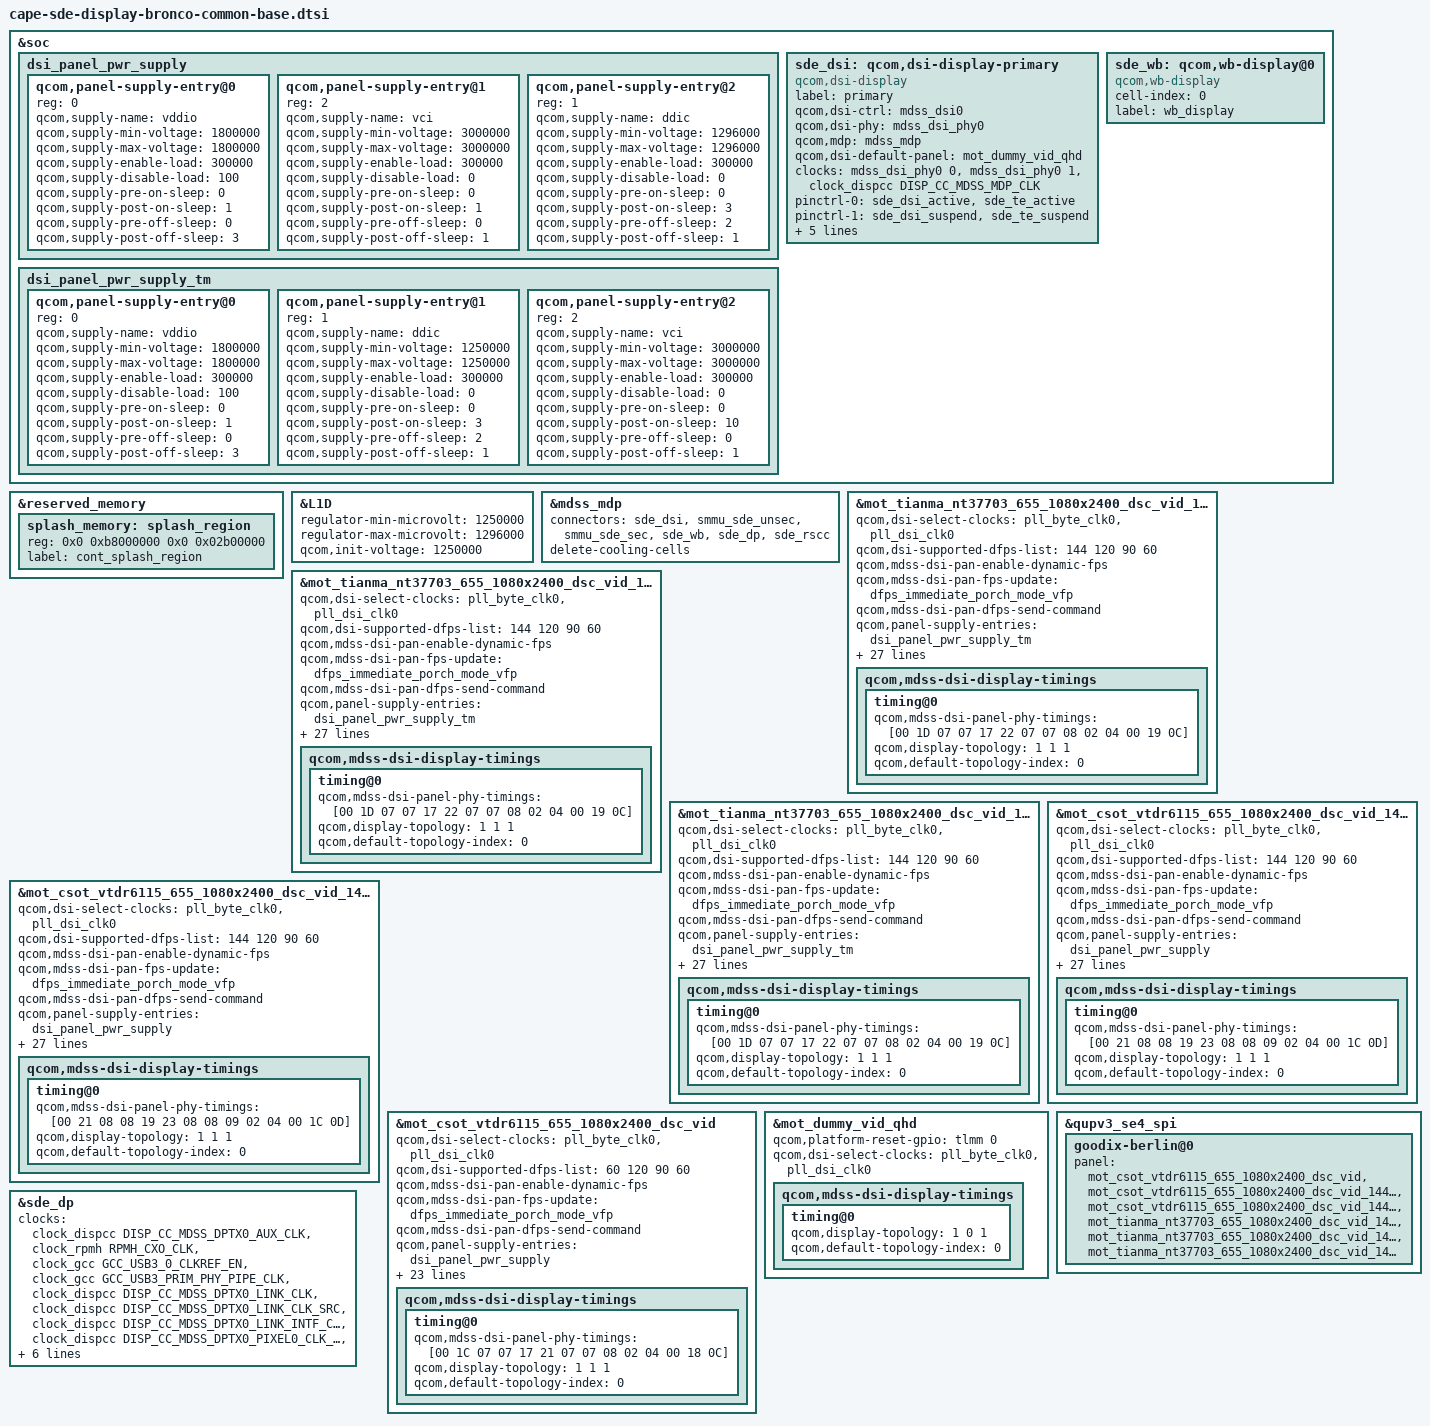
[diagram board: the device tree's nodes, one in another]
/*
   this is original from cape-sde-display-hiphi-common-base.dtsi
*/
#include <dt-bindings/clock/qcom,gcc-waipio.h>
#include <dt-bindings/clock/qcom,rpmh.h>
#include "cape-sde-display-pinctrl.dtsi"
#include "dsi-panel-mot-dummy-qhd-video.dtsi"
#include <dt-bindings/clock/qcom,dispcc-waipio.h>
#include "dsi-panel-mot-csot-vtdr6115-655-1080x2400-dsc-video-common.dtsi"
#include "dsi-panel-mot-csot-vtdr6115-655-1080x2400-dsc-video-144hz-common.dtsi"
#include "dsi-panel-mot-csot-vtdr6115-655-1080x2400-dsc-video-144hz-common-v1.dtsi"
#include "dsi-panel-mot-tianma-nt37703-655-1080x2400-dsc-video-144hz-common.dtsi"
#include "dsi-panel-mot-tianma-nt37703-655-1080x2400-dsc-video-144hz-common-v1.dtsi"
#include "dsi-panel-mot-tianma-nt37703-655-1080x2400-dsc-video-144hz-common-v2.dtsi"

&soc {

	dsi_panel_pwr_supply: dsi_panel_pwr_supply {
		#address-cells = <1>;
		#size-cells = <0>;

		qcom,panel-supply-entry@0 {
			reg = <0>;
			qcom,supply-name = "vddio";
			qcom,supply-min-voltage = <1800000>;
			qcom,supply-max-voltage = <1800000>;
			qcom,supply-enable-load = <300000>;
			qcom,supply-disable-load = <100>;
			qcom,supply-pre-on-sleep = <0>;
			qcom,supply-post-on-sleep = <1>;
			qcom,supply-pre-off-sleep = <0>;
			qcom,supply-post-off-sleep = <3>;
		};

		qcom,panel-supply-entry@1 {
			reg = <2>;
			qcom,supply-name = "vci";
			qcom,supply-min-voltage = <3000000>;
			qcom,supply-max-voltage = <3000000>;
			qcom,supply-enable-load = <300000>;
			qcom,supply-disable-load = <0>;
			qcom,supply-pre-on-sleep = <0>;
			qcom,supply-post-on-sleep = <1>;
			qcom,supply-pre-off-sleep = <0>;
			qcom,supply-post-off-sleep = <1>;
		};

		qcom,panel-supply-entry@2 {
			reg = <1>;
			qcom,supply-name = "ddic";
			qcom,supply-min-voltage = <1296000>;
			qcom,supply-max-voltage = <1296000>;
			qcom,supply-enable-load = <300000>;
			qcom,supply-disable-load = <0>;
			qcom,supply-pre-on-sleep = <0>;
			qcom,supply-post-on-sleep = <3>;
			qcom,supply-pre-off-sleep = <2>;
			qcom,supply-post-off-sleep = <1>;
		};
	};

	dsi_panel_pwr_supply_tm: dsi_panel_pwr_supply_tm {
		#address-cells = <1>;
		#size-cells = <0>;

		qcom,panel-supply-entry@0 {
			reg = <0>;
			qcom,supply-name = "vddio";
			qcom,supply-min-voltage = <1800000>;
			qcom,supply-max-voltage = <1800000>;
			qcom,supply-enable-load = <300000>;
			qcom,supply-disable-load = <100>;
			qcom,supply-pre-on-sleep = <0>;
			qcom,supply-post-on-sleep = <1>;
			qcom,supply-pre-off-sleep = <0>;
			qcom,supply-post-off-sleep = <3>;
		};


		qcom,panel-supply-entry@1 {
			reg = <1>;
			qcom,supply-name = "ddic";
			qcom,supply-min-voltage = <1250000>;
			qcom,supply-max-voltage = <1250000>;
			qcom,supply-enable-load = <300000>;
			qcom,supply-disable-load = <0>;
			qcom,supply-pre-on-sleep = <0>;
			qcom,supply-post-on-sleep = <3>;
			qcom,supply-pre-off-sleep = <2>;
			qcom,supply-post-off-sleep = <1>;
		};

		qcom,panel-supply-entry@2 {
			reg = <2>;
			qcom,supply-name = "vci";
			qcom,supply-min-voltage = <3000000>;
			qcom,supply-max-voltage = <3000000>;
			qcom,supply-enable-load = <300000>;
			qcom,supply-disable-load = <0>;
			qcom,supply-pre-on-sleep = <0>;
			qcom,supply-post-on-sleep = <10>;
			qcom,supply-pre-off-sleep = <0>;
			qcom,supply-post-off-sleep = <1>;
		};

	};

	sde_dsi: qcom,dsi-display-primary {
		compatible = "qcom,dsi-display";
		label = "primary";

		qcom,dsi-ctrl = <&mdss_dsi0>;
		qcom,dsi-phy = <&mdss_dsi_phy0>;

		qcom,mdp = <&mdss_mdp>;
		qcom,dsi-default-panel = <&mot_dummy_vid_qhd>;
	};
};


&soc {
	sde_wb: qcom,wb-display@0 {
		compatible = "qcom,wb-display";
		cell-index = <0>;
		label = "wb_display";
	};
};

&reserved_memory {
	splash_memory: splash_region {
		reg = <0x0 0xb8000000 0x0 0x02b00000>;
		label = "cont_splash_region";
	};
};

&sde_dsi {
	clocks = <&mdss_dsi_phy0 0>,
			<&mdss_dsi_phy0 1>,

			 /*
			  * Currently the dsi clock handles are under the dsi
			  * controller DT node. As soon as the controller probe
			  * finishes, the dispcc sync state can get called before
			  * the dsi_display probe potentially disturbing the clock
			  * votes for cont_splash use case. Hence we are no longer
			  * protected by the component model in this case against the
			  * disp cc sync state getting triggered after the dsi_ctrl
			  * probe. To protect against this incorrect sync state trigger
			  * add this dummy MDP clk vote handle to the dsi_display
			  * DT node. Since the dsi_display driver does not parse
			  * MDP clock nodes, no actual vote shall be added and this
			  * change is done just to satisfy sync state requirements.
			  */
			 <&clock_dispcc DISP_CC_MDSS_MDP_CLK>;
	clock-names = "pll_byte_clk0", "pll_dsi_clk0",
			"mdp_core_clk";

	pinctrl-names = "panel_active", "panel_suspend";
	pinctrl-0 = <&sde_dsi_active &sde_te_active>;
	pinctrl-1 = <&sde_dsi_suspend &sde_te_suspend>;

	qcom,platform-te-gpio = <&tlmm 86 0>;
	qcom,panel-te-source = <0>;

	vddio-supply = <&L12C>;
	ddic-supply = <&L1D>;
	vci-supply = <&L13C>;
};

&L1D {
	regulator-min-microvolt = <1250000>;
	regulator-max-microvolt = <1296000>;
	qcom,init-voltage = <1250000>;
};

&mdss_mdp {
	connectors = <&sde_dsi &smmu_sde_unsec &smmu_sde_sec &sde_wb &sde_dp &sde_rscc>;
	delete-cooling-cells;
};

&mot_tianma_nt37703_655_1080x2400_dsc_vid_144hz_v2 {
	qcom,dsi-select-clocks = "pll_byte_clk0", "pll_dsi_clk0";

	qcom,dsi-supported-dfps-list = <144 120 90 60>;
	qcom,mdss-dsi-pan-enable-dynamic-fps;
	qcom,mdss-dsi-pan-fps-update = "dfps_immediate_porch_mode_vfp";
	qcom,mdss-dsi-pan-dfps-send-command;

	//qcom,dsi-dyn-clk-enable;

	qcom,panel-supply-entries = <&dsi_panel_pwr_supply_tm>;
	qcom,mdss-dsi-no-panel-on-read-support;
	qcom,mdss-dsi-bl-pmic-control-type = "bl_ctrl_dcs";
	qcom,mdss-dsi-bl-min-level = <1>;
	qcom,mdss-dsi-bl-max-level = <4095>;
	//qcom,mdss-dsi-bl-default-level = <1024>;
	qcom,mdss-brightness-max-level = <4095>;
	qcom,platform-reset-gpio = <&tlmm 0 0>;
	qcom,bl-dsc-cmd-state = "dsi_hs_mode";
	qcom,mdss-dsi-bl-is-exponent;

	qcom,mdss-dsi-panel-hdr-enabled;
	qcom,mdss-dsi-panel-hdr-color-primaries = <14950 15750 34000
	        16000 13000 35500 7000 2500>;
	qcom,mdss-dsi-panel-peak-brightness = <5000000>;
	qcom,mdss-dsi-panel-blackness-level = <100>;

	qcom,mdss-dsi-panel-status-check-mode = "reg_read";
	qcom,mdss-dsi-panel-status-command = [06 01 00 01 00 00 01 0A];
	qcom,mdss-dsi-panel-status-command-state = "dsi_lp_mode";
	qcom,mdss-dsi-panel-status-value = <0x9C>;
	qcom,mdss-dsi-panel-status-read-length = <1>;
	qcom,esd-check-enabled;

	qcom,cellid-read-enabled;
	qcom,mdss-dsi-panel-cellid-read-length = <23>;
	qcom,mdss-dsi-panel-cellid-command = [
		39 01 00 00 00 00 03 F0 AA 10
		06 01 00 01 00 00 01 AC];

	qcom,mdss-dsi-display-timings {
		timing@0 {
			//qcom,mdss-dsi-panel-clockrate = <400000000>;
			qcom,mdss-dsi-panel-phy-timings = [00 1D 07 07 17 22 07
				07 08 02 04 00 19 0C];
			qcom,display-topology = <1 1 1>;
			qcom,default-topology-index = <0>;
		};
	};
};

&mot_tianma_nt37703_655_1080x2400_dsc_vid_144hz_v1 {
	qcom,dsi-select-clocks = "pll_byte_clk0", "pll_dsi_clk0";

	qcom,dsi-supported-dfps-list = <144 120 90 60>;
	qcom,mdss-dsi-pan-enable-dynamic-fps;
	qcom,mdss-dsi-pan-fps-update = "dfps_immediate_porch_mode_vfp";
	qcom,mdss-dsi-pan-dfps-send-command;

	//qcom,dsi-dyn-clk-enable;

	qcom,panel-supply-entries = <&dsi_panel_pwr_supply_tm>;
	qcom,mdss-dsi-no-panel-on-read-support;
	qcom,mdss-dsi-bl-pmic-control-type = "bl_ctrl_dcs";
	qcom,mdss-dsi-bl-min-level = <1>;
	qcom,mdss-dsi-bl-max-level = <4095>;
	//qcom,mdss-dsi-bl-default-level = <1024>;
	qcom,mdss-brightness-max-level = <4095>;
	qcom,platform-reset-gpio = <&tlmm 0 0>;
	qcom,bl-dsc-cmd-state = "dsi_hs_mode";
	qcom,mdss-dsi-bl-is-exponent;

	qcom,mdss-dsi-panel-hdr-enabled;
	qcom,mdss-dsi-panel-hdr-color-primaries = <14950 15750 34000
	        16000 13000 35500 7000 2500>;
	qcom,mdss-dsi-panel-peak-brightness = <5000000>;
	qcom,mdss-dsi-panel-blackness-level = <100>;

	qcom,mdss-dsi-panel-status-check-mode = "reg_read";
	qcom,mdss-dsi-panel-status-command = [06 01 00 01 00 00 01 0A];
	qcom,mdss-dsi-panel-status-command-state = "dsi_lp_mode";
	qcom,mdss-dsi-panel-status-value = <0x9C>;
	qcom,mdss-dsi-panel-status-read-length = <1>;
	qcom,esd-check-enabled;

	qcom,cellid-read-enabled;
	qcom,mdss-dsi-panel-cellid-read-length = <23>;
	qcom,mdss-dsi-panel-cellid-command = [
		39 01 00 00 00 00 03 F0 AA 10
		06 01 00 01 00 00 01 AC];

	qcom,mdss-dsi-display-timings {
		timing@0 {
			//qcom,mdss-dsi-panel-clockrate = <400000000>;
			qcom,mdss-dsi-panel-phy-timings = [00 1D 07 07 17 22 07
				07 08 02 04 00 19 0C];
			qcom,display-topology = <1 1 1>;
			qcom,default-topology-index = <0>;
		};
	};
};

&mot_tianma_nt37703_655_1080x2400_dsc_vid_144hz {
	qcom,dsi-select-clocks = "pll_byte_clk0", "pll_dsi_clk0";

	qcom,dsi-supported-dfps-list = <144 120 90 60>;
	qcom,mdss-dsi-pan-enable-dynamic-fps;
	qcom,mdss-dsi-pan-fps-update = "dfps_immediate_porch_mode_vfp";
	qcom,mdss-dsi-pan-dfps-send-command;

	//qcom,dsi-dyn-clk-enable;

	qcom,panel-supply-entries = <&dsi_panel_pwr_supply_tm>;
	qcom,mdss-dsi-no-panel-on-read-support;
	qcom,mdss-dsi-bl-pmic-control-type = "bl_ctrl_dcs";
	qcom,mdss-dsi-bl-min-level = <1>;
	qcom,mdss-dsi-bl-max-level = <4095>;
	//qcom,mdss-dsi-bl-default-level = <1024>;
	qcom,mdss-brightness-max-level = <4095>;
	qcom,platform-reset-gpio = <&tlmm 0 0>;
	qcom,bl-dsc-cmd-state = "dsi_hs_mode";
	qcom,mdss-dsi-bl-is-exponent;

	qcom,mdss-dsi-panel-hdr-enabled;
	qcom,mdss-dsi-panel-hdr-color-primaries = <14950 15750 34000
	        16000 13000 35500 7000 2500>;
	qcom,mdss-dsi-panel-peak-brightness = <5000000>;
	qcom,mdss-dsi-panel-blackness-level = <100>;

	qcom,mdss-dsi-panel-status-check-mode = "reg_read";
	qcom,mdss-dsi-panel-status-command = [06 01 00 01 00 00 01 0A];
	qcom,mdss-dsi-panel-status-command-state = "dsi_lp_mode";
	qcom,mdss-dsi-panel-status-value = <0x9C>;
	qcom,mdss-dsi-panel-status-read-length = <1>;
	qcom,esd-check-enabled;

	qcom,cellid-read-enabled;
	qcom,mdss-dsi-panel-cellid-read-length = <23>;
	qcom,mdss-dsi-panel-cellid-command = [
		39 01 00 00 00 00 03 F0 AA 10
		06 01 00 01 00 00 01 AC];

	qcom,mdss-dsi-display-timings {
		timing@0 {
			//qcom,mdss-dsi-panel-clockrate = <400000000>;
			qcom,mdss-dsi-panel-phy-timings = [00 1D 07 07 17 22 07
				07 08 02 04 00 19 0C];
			qcom,display-topology = <1 1 1>;
			qcom,default-topology-index = <0>;
		};
	};
};

&mot_csot_vtdr6115_655_1080x2400_dsc_vid_144hz_v1 {
	qcom,dsi-select-clocks = "pll_byte_clk0", "pll_dsi_clk0";

	qcom,dsi-supported-dfps-list = <144 120 90 60>;
	qcom,mdss-dsi-pan-enable-dynamic-fps;
	qcom,mdss-dsi-pan-fps-update = "dfps_immediate_porch_mode_vfp";
	qcom,mdss-dsi-pan-dfps-send-command;

	//qcom,dsi-dyn-clk-enable;

	qcom,panel-supply-entries = <&dsi_panel_pwr_supply>;
	qcom,mdss-dsi-no-panel-on-read-support;
	qcom,mdss-dsi-bl-pmic-control-type = "bl_ctrl_dcs";
	qcom,mdss-dsi-bl-min-level = <1>;
	qcom,mdss-dsi-bl-max-level = <4095>;
	//qcom,mdss-dsi-bl-default-level = <1024>;
	qcom,mdss-brightness-max-level = <4095>;
	qcom,platform-reset-gpio = <&tlmm 0 0>;
	qcom,bl-dsc-cmd-state = "dsi_hs_mode";
	qcom,mdss-dsi-bl-is-exponent;

	qcom,mdss-dsi-panel-hdr-enabled;
	qcom,mdss-dsi-panel-hdr-color-primaries = <14950 15750 34000
	        16000 13000 35500 7000 2500>;
	qcom,mdss-dsi-panel-peak-brightness = <5000000>;
	qcom,mdss-dsi-panel-blackness-level = <100>;

	qcom,mdss-dsi-panel-status-check-mode = "reg_read";
	qcom,mdss-dsi-panel-status-command = [06 01 00 01 00 00 01 66];
	qcom,mdss-dsi-panel-status-command-state = "dsi_lp_mode";
	qcom,mdss-dsi-panel-status-value = <0 0 0>;
	qcom,mdss-dsi-panel-status-read-length = <3>;
	qcom,esd-check-enabled;

	qcom,cellid-read-enabled;
	qcom,mdss-dsi-panel-cellid-read-length = <23>;
	qcom,mdss-dsi-panel-cellid-command = [06 01 00 01 00 00 01 5A];

	qcom,mdss-dsi-display-timings {
		timing@0 {
			//qcom,mdss-dsi-panel-clockrate = <400000000>;
			qcom,mdss-dsi-panel-phy-timings = [00 21 08 08 19 23 08
				08 09 02 04 00 1C 0D];
			qcom,display-topology = <1 1 1>;
			qcom,default-topology-index = <0>;
		};
	};
};

&mot_csot_vtdr6115_655_1080x2400_dsc_vid_144hz {
	qcom,dsi-select-clocks = "pll_byte_clk0", "pll_dsi_clk0";

	qcom,dsi-supported-dfps-list = <144 120 90 60>;
	qcom,mdss-dsi-pan-enable-dynamic-fps;
	qcom,mdss-dsi-pan-fps-update = "dfps_immediate_porch_mode_vfp";
	qcom,mdss-dsi-pan-dfps-send-command;

	//qcom,dsi-dyn-clk-enable;

	qcom,panel-supply-entries = <&dsi_panel_pwr_supply>;
	qcom,mdss-dsi-no-panel-on-read-support;
	qcom,mdss-dsi-bl-pmic-control-type = "bl_ctrl_dcs";
	qcom,mdss-dsi-bl-min-level = <1>;
	qcom,mdss-dsi-bl-max-level = <4095>;
	//qcom,mdss-dsi-bl-default-level = <1024>;
	qcom,mdss-brightness-max-level = <4095>;
	qcom,platform-reset-gpio = <&tlmm 0 0>;
	qcom,bl-dsc-cmd-state = "dsi_hs_mode";
	qcom,mdss-dsi-bl-is-exponent;

	qcom,mdss-dsi-panel-hdr-enabled;
	qcom,mdss-dsi-panel-hdr-color-primaries = <14950 15750 34000
	        16000 13000 35500 7000 2500>;
	qcom,mdss-dsi-panel-peak-brightness = <5000000>;
	qcom,mdss-dsi-panel-blackness-level = <100>;

	qcom,mdss-dsi-panel-status-check-mode = "reg_read";
	qcom,mdss-dsi-panel-status-command = [06 01 00 01 00 00 01 66];
	qcom,mdss-dsi-panel-status-command-state = "dsi_lp_mode";
	qcom,mdss-dsi-panel-status-value = <0 0 0>;
	qcom,mdss-dsi-panel-status-read-length = <3>;
	qcom,esd-check-enabled;

	qcom,cellid-read-enabled;
	qcom,mdss-dsi-panel-cellid-read-length = <23>;
	qcom,mdss-dsi-panel-cellid-command = [06 01 00 01 00 00 01 5A];

	qcom,mdss-dsi-display-timings {
		timing@0 {
			//qcom,mdss-dsi-panel-clockrate = <400000000>;
			qcom,mdss-dsi-panel-phy-timings = [00 21 08 08 19 23 08
				08 09 02 04 00 1C 0D];
			qcom,display-topology = <1 1 1>;
			qcom,default-topology-index = <0>;
		};
	};
};

&mot_csot_vtdr6115_655_1080x2400_dsc_vid {
	qcom,dsi-select-clocks = "pll_byte_clk0", "pll_dsi_clk0";

	qcom,dsi-supported-dfps-list = <60 120 90 60>;
	qcom,mdss-dsi-pan-enable-dynamic-fps;
	qcom,mdss-dsi-pan-fps-update = "dfps_immediate_porch_mode_vfp";
	qcom,mdss-dsi-pan-dfps-send-command;

	//qcom,dsi-dyn-clk-enable;

	qcom,panel-supply-entries = <&dsi_panel_pwr_supply>;
	qcom,mdss-dsi-no-panel-on-read-support;
	qcom,mdss-dsi-bl-pmic-control-type = "bl_ctrl_dcs";
	qcom,mdss-dsi-bl-min-level = <1>;
	qcom,mdss-dsi-bl-max-level = <4095>;
	//qcom,mdss-dsi-bl-default-level = <1024>;
	qcom,mdss-brightness-max-level = <4095>;
	qcom,platform-reset-gpio = <&tlmm 0 0>;
	qcom,bl-dsc-cmd-state = "dsi_hs_mode";
	qcom,mdss-dsi-bl-is-exponent;

	qcom,mdss-dsi-panel-hdr-enabled;
	qcom,mdss-dsi-panel-hdr-color-primaries = <14950 15750 34000
	        16000 13000 35500 7000 2500>;
	qcom,mdss-dsi-panel-peak-brightness = <5000000>;
	qcom,mdss-dsi-panel-blackness-level = <100>;

	qcom,mdss-dsi-panel-status-check-mode = "reg_read";
	qcom,mdss-dsi-panel-status-command = [06 01 00 01 00 00 01 66];
	qcom,mdss-dsi-panel-status-command-state = "dsi_lp_mode";
	qcom,mdss-dsi-panel-status-value = <0 0 0>;
	qcom,mdss-dsi-panel-status-read-length = <3>;
	qcom,esd-check-enabled;
	//qcom,mot_nt37701A_read_cellid;

	qcom,mdss-dsi-display-timings {
		timing@0 {
			//qcom,mdss-dsi-panel-clockrate = <400000000>;
			qcom,mdss-dsi-panel-phy-timings = [00 1C 07 07 17 21 07
				07 08 02 04 00 18 0C];
			qcom,display-topology = <1 1 1>;
			qcom,default-topology-index = <0>;
		};
	};
};

&mot_dummy_vid_qhd {
	qcom,platform-reset-gpio = <&tlmm 0 0>;

	qcom,dsi-select-clocks = "pll_byte_clk0", "pll_dsi_clk0";
	qcom,mdss-dsi-display-timings {
		timing@0 {
			qcom,display-topology = <1 0 1>;
			qcom,default-topology-index = <0>;
		};
	};
};

&sde_dsi {
	qcom,dsi-default-panel = <&mot_dummy_vid_qhd>;
};

&qupv3_se4_spi {
	goodix-berlin@0 {
		panel = <&mot_csot_vtdr6115_655_1080x2400_dsc_vid
			&mot_csot_vtdr6115_655_1080x2400_dsc_vid_144hz
			&mot_csot_vtdr6115_655_1080x2400_dsc_vid_144hz_v1
			&mot_tianma_nt37703_655_1080x2400_dsc_vid_144hz
			&mot_tianma_nt37703_655_1080x2400_dsc_vid_144hz_v1
			&mot_tianma_nt37703_655_1080x2400_dsc_vid_144hz_v2>;
	};
};

&sde_dp {
	#clock-cells = <1>;
	clocks =  <&clock_dispcc DISP_CC_MDSS_DPTX0_AUX_CLK>,
		<&clock_rpmh RPMH_CXO_CLK>,
		<&clock_gcc GCC_USB3_0_CLKREF_EN>,
		<&clock_gcc GCC_USB3_PRIM_PHY_PIPE_CLK>,
		<&clock_dispcc DISP_CC_MDSS_DPTX0_LINK_CLK>,
		<&clock_dispcc DISP_CC_MDSS_DPTX0_LINK_CLK_SRC>,
		<&clock_dispcc DISP_CC_MDSS_DPTX0_LINK_INTF_CLK>,
		<&clock_dispcc DISP_CC_MDSS_DPTX0_PIXEL0_CLK_SRC>,
		<&sde_dp 1>,
		<&clock_dispcc DISP_CC_MDSS_DPTX0_PIXEL1_CLK_SRC>,
		<&clock_dispcc DISP_CC_MDSS_DPTX0_PIXEL0_CLK>,
		<&clock_dispcc DISP_CC_MDSS_DPTX0_PIXEL1_CLK>;
	clock-names = "core_aux_clk", "rpmh_cxo_clk", "core_usb_ref_clk_src",
		"core_usb_pipe_clk", "link_clk", "link_clk_src", "link_iface_clk",
		"pixel_clk_rcg", "pixel_parent", "pixel1_clk_rcg",
		"strm0_pixel_clk", "strm1_pixel_clk";
	clock-mmrm = <0 0 0 0 0 DISP_CC_MDSS_DPTX0_LINK_CLK_SRC 0 0 0 0 0 0>;
};
